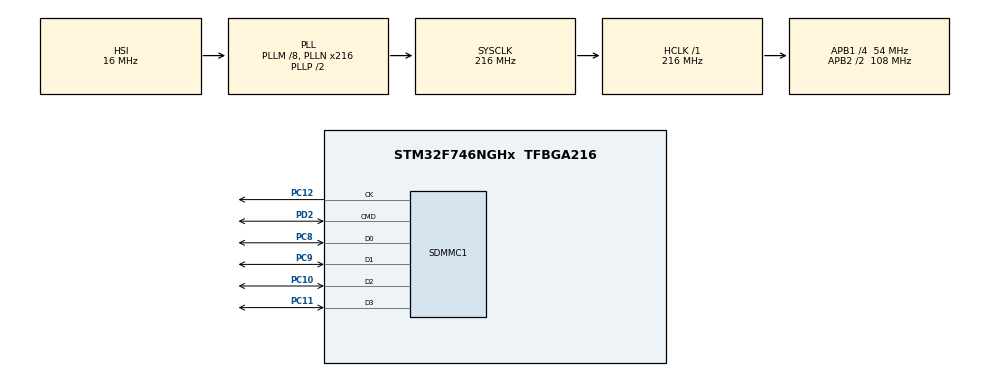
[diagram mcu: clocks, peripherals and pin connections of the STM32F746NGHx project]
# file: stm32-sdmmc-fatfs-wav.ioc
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Mcu.Family=STM32F7
Dma.SDMMC1_TX.1.Instance=DMA2_Stream6
RCC.CortexFreq_Value=216000000
Dma.SDMMC1_RX.0.PeriphInc=DMA_PINC_DISABLE
Dma.SDMMC1_RX.0.MemInc=DMA_MINC_ENABLE
VP_FATFS_VS_SDIO.Mode=SDIO
PC12.Signal=SDMMC1_CK
PC11.Signal=SDMMC1_D3
PC10.Signal=SDMMC1_D2
PC8.Signal=SDMMC1_D0
PC10.Mode=SD_4_bits_Wide_bus
Dma.SDMMC1_RX.0.PeriphDataAlignment=DMA_PDATAALIGN_WORD
Dma.SDMMC1_RX.0.Instance=DMA2_Stream3
Dma.SDMMC1_RX.0.FIFOMode=DMA_FIFOMODE_ENABLE
Dma.SDMMC1_RX.0.Priority=DMA_PRIORITY_LOW
RCC.APB1CLKDivider=RCC_HCLK_DIV4
RCC.SYSCLKSource=RCC_SYSCLKSOURCE_PLLCLK
ProjectManager.StackSize=0x400
RCC.PLLSAIRDiv=RCC_PLLSAIDIVR_8
Dma.SDMMC1_TX.1.FIFOThreshold=DMA_FIFO_THRESHOLD_FULL
NVIC.SDMMC1_IRQn=true\:0\:0\:false\:false\:true\:true\:true
Dma.SDMMC1_TX.1.PeriphBurst=DMA_PBURST_INC4
ProjectManager.TargetToolchain=STM32CubeIDE
RCC.PLL48CLockSelection=RCC_CLK48SOURCE_PLLSAIP
RCC.HCLKFreq_Value=216000000
RCC.APB2TimFreq_Value=216000000
RCC.USBFreq_Value=50000000
NVIC.DMA2_Stream3_IRQn=true\:0\:0\:false\:false\:true\:false\:true
NVIC.DMA2_Stream6_IRQn=true\:0\:0\:false\:false\:true\:false\:true
RCC.LSE_VALUE=32768
RCC.AHBFreq_Value=216000000
PD2.Mode=SD_4_bits_Wide_bus
RCC.HSE_VALUE=25000000
PC12.Mode=SD_4_bits_Wide_bus
board=STM32F746G-DISCO
RCC.VCOOutputFreq_Value=432000000
FATFS.USE_DMA_CODE_SD=1
RCC.APB2Freq_Value=108000000
Dma.SDMMC1_RX.0.Direction=DMA_PERIPH_TO_MEMORY
PC9.Mode=SD_4_bits_Wide_bus
Dma.SDMMC1_RX.0.MemBurst=DMA_MBURST_INC4
Dma.SDMMC1_TX.1.Priority=DMA_PRIORITY_LOW
Dma.SDMMC1_TX.1.FIFOMode=DMA_FIFOMODE_ENABLE
Mcu.Name=STM32F746NGHx
PC8.Mode=SD_4_bits_Wide_bus
RCC.SYSCLKFreq_VALUE=216000000
Mcu.Package=TFBGA216
RCC.SDMMCClockSelection=RCC_SDMMC1CLKSOURCE_CLK48
Dma.SDMMC1_TX.1.MemBurst=DMA_MBURST_INC4
Dma.SDMMC1_RX.0.FIFOThreshold=DMA_FIFO_THRESHOLD_FULL
Dma.SDMMC1_TX.1.PeriphDataAlignment=DMA_PDATAALIGN_WORD
Dma.SDMMC1_RX.0.PeriphBurst=DMA_PBURST_INC4
ProjectManager.HeapSize=0x200
PC11.Mode=SD_4_bits_Wide_bus
Dma.SDMMC1_TX.1.MemDataAlignment=DMA_MDATAALIGN_WORD
RCC.HSI_VALUE=16000000
RCC.PLLSAIN=50
RCC.PLLQ=9
NVIC.PriorityGroup=NVIC_PRIORITYGROUP_4
RCC.PLLSAIR=5
RCC.APB2CLKDivider=RCC_HCLK_DIV2
RCC.PLLM=8
RCC.PLLN=216
Dma.Request1=SDMMC1_TX
RCC.APB1TimFreq_Value=108000000
Dma.SDMMC1_TX.1.MemInc=DMA_MINC_ENABLE
PC9.Signal=SDMMC1_D1
PD2.Signal=SDMMC1_CMD
Dma.SDMMC1_RX.0.Mode=DMA_PFCTRL
Dma.Request0=SDMMC1_RX
RCC.APB1Freq_Value=54000000
Dma.SDMMC1_RX.0.MemDataAlignment=DMA_MDATAALIGN_WORD
Dma.SDMMC1_TX.1.Mode=DMA_PFCTRL
Dma.SDMMC1_TX.1.PeriphInc=DMA_PINC_DISABLE
RCC.PLLI2SN=100
Dma.SDMMC1_TX.1.Direction=DMA_MEMORY_TO_PERIPH

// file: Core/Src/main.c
/* USER CODE BEGIN Header */
/**
 ******************************************************************************
 * @file           : main.c
 * @brief          : Main program body
 ******************************************************************************
 * @attention
 *
 * <h2><center>&copy; Copyright (c) 2021 STMicroelectronics.
 * All rights reserved.</center></h2>
 *
 * This software component is licensed by ST under Ultimate Liberty license
 * SLA0044, the "License"; You may not use this file except in compliance with
 * the License. You may obtain a copy of the License at:
 *                             www.st.com/SLA0044
 *
 ******************************************************************************
 */
/* USER CODE END Header */
#include "main.h"
#include "fatfs.h"

SD_HandleTypeDef hsd1;
DMA_HandleTypeDef hdma_sdmmc1_rx;
DMA_HandleTypeDef hdma_sdmmc1_tx;

void SystemClock_Config(void);
static void MX_GPIO_Init(void);
static void MX_DMA_Init(void);
static void MX_SDMMC1_SD_Init(void);

int main(void) {
	/* USER CODE BEGIN 1 */
	WAVE_FormatTypeDef info_HELLO_WAV = { 0 };
	/* USER CODE END 1 */

	/* MCU Configuration--------------------------------------------------------*/

	/* Reset of all peripherals, Initializes the Flash interface and the Systick. */
	HAL_Init();

	/* Configure the system clock */
	SystemClock_Config();

	/* Initialize all configured peripherals */
	MX_GPIO_Init();
	MX_DMA_Init();
	MX_SDMMC1_SD_Init();
	MX_FATFS_Init();
	/* USER CODE BEGIN 2 */
	if (WAV_StorageParse() != FR_OK) {
		while (1) {
			/* Something happened */
		}
	}
	if (WAV_GetFileInfo(WAV_GetFileDescriptor("HELLO.WAV"), &info_HELLO_WAV)
			!= WAV_OK) {
		while (1) {
			/* Something happened */
		}
	}
	/* USER CODE END 2 */

	/* Infinite loop */
	while (1) {

	}
}

void SystemClock_Config(void) {
	RCC_OscInitTypeDef RCC_OscInitStruct = { 0 };
	RCC_ClkInitTypeDef RCC_ClkInitStruct = { 0 };
	RCC_PeriphCLKInitTypeDef PeriphClkInitStruct = { 0 };

	/** Configure the main internal regulator output voltage
	 */
	__HAL_RCC_PWR_CLK_ENABLE();
	__HAL_PWR_VOLTAGESCALING_CONFIG(PWR_REGULATOR_VOLTAGE_SCALE1);
	/** Initializes the RCC Oscillators according to the specified parameters
	 * in the RCC_OscInitTypeDef structure.
	 */
	RCC_OscInitStruct.OscillatorType = RCC_OSCILLATORTYPE_HSI;
	RCC_OscInitStruct.HSIState = RCC_HSI_ON;
	RCC_OscInitStruct.HSICalibrationValue = RCC_HSICALIBRATION_DEFAULT;
	RCC_OscInitStruct.PLL.PLLState = RCC_PLL_ON;
	RCC_OscInitStruct.PLL.PLLSource = RCC_PLLSOURCE_HSI;
	RCC_OscInitStruct.PLL.PLLM = 8;
	RCC_OscInitStruct.PLL.PLLN = 216;
	RCC_OscInitStruct.PLL.PLLP = RCC_PLLP_DIV2;
	RCC_OscInitStruct.PLL.PLLQ = 9;
	if (HAL_RCC_OscConfig(&RCC_OscInitStruct) != HAL_OK) {
		Error_Handler();
	}
	/** Activate the Over-Drive mode
	 */
	if (HAL_PWREx_EnableOverDrive() != HAL_OK) {
		Error_Handler();
	}
	/** Initializes the CPU, AHB and APB buses clocks
	 */
	RCC_ClkInitStruct.ClockType = RCC_CLOCKTYPE_HCLK | RCC_CLOCKTYPE_SYSCLK
			| RCC_CLOCKTYPE_PCLK1 | RCC_CLOCKTYPE_PCLK2;
	RCC_ClkInitStruct.SYSCLKSource = RCC_SYSCLKSOURCE_PLLCLK;
	RCC_ClkInitStruct.AHBCLKDivider = RCC_SYSCLK_DIV1;
	RCC_ClkInitStruct.APB1CLKDivider = RCC_HCLK_DIV4;
	RCC_ClkInitStruct.APB2CLKDivider = RCC_HCLK_DIV2;

	if (HAL_RCC_ClockConfig(&RCC_ClkInitStruct, FLASH_LATENCY_7) != HAL_OK) {
		Error_Handler();
	}
	PeriphClkInitStruct.PeriphClockSelection = RCC_PERIPHCLK_SDMMC1
			| RCC_PERIPHCLK_CLK48;
	PeriphClkInitStruct.PLLSAI.PLLSAIN = 50;
	PeriphClkInitStruct.PLLSAI.PLLSAIR = 5;
	PeriphClkInitStruct.PLLSAI.PLLSAIQ = 2;
	PeriphClkInitStruct.PLLSAI.PLLSAIP = RCC_PLLSAIP_DIV2;
	PeriphClkInitStruct.PLLSAIDivQ = 1;
	PeriphClkInitStruct.PLLSAIDivR = RCC_PLLSAIDIVR_8;
	PeriphClkInitStruct.Clk48ClockSelection = RCC_CLK48SOURCE_PLLSAIP;
	PeriphClkInitStruct.Sdmmc1ClockSelection = RCC_SDMMC1CLKSOURCE_CLK48;
	if (HAL_RCCEx_PeriphCLKConfig(&PeriphClkInitStruct) != HAL_OK) {
		Error_Handler();
	}
}

static void MX_SDMMC1_SD_Init(void) {

	hsd1.Instance = SDMMC1;
	hsd1.Init.ClockEdge = SDMMC_CLOCK_EDGE_RISING;
	hsd1.Init.ClockBypass = SDMMC_CLOCK_BYPASS_DISABLE;
	hsd1.Init.ClockPowerSave = SDMMC_CLOCK_POWER_SAVE_DISABLE;
	hsd1.Init.BusWide = SDMMC_BUS_WIDE_1B;
	hsd1.Init.HardwareFlowControl = SDMMC_HARDWARE_FLOW_CONTROL_DISABLE;
	hsd1.Init.ClockDiv = 0;
}

static void MX_DMA_Init(void) {

	/* DMA controller clock enable */
	__HAL_RCC_DMA2_CLK_ENABLE();

	/* DMA interrupt init */
	/* DMA2_Stream3_IRQn interrupt configuration */
	HAL_NVIC_SetPriority(DMA2_Stream3_IRQn, 0, 0);
	HAL_NVIC_EnableIRQ(DMA2_Stream3_IRQn);
	/* DMA2_Stream6_IRQn interrupt configuration */
	HAL_NVIC_SetPriority(DMA2_Stream6_IRQn, 0, 0);
	HAL_NVIC_EnableIRQ(DMA2_Stream6_IRQn);
}

static void MX_GPIO_Init(void) {

	/* GPIO Ports Clock Enable */
	__HAL_RCC_GPIOC_CLK_ENABLE();
	__HAL_RCC_GPIOD_CLK_ENABLE();
}

void Error_Handler(void) {
	__disable_irq();
	while (1) {
	}
}

/************************ (C) COPYRIGHT STMicroelectronics *****END OF FILE****/
